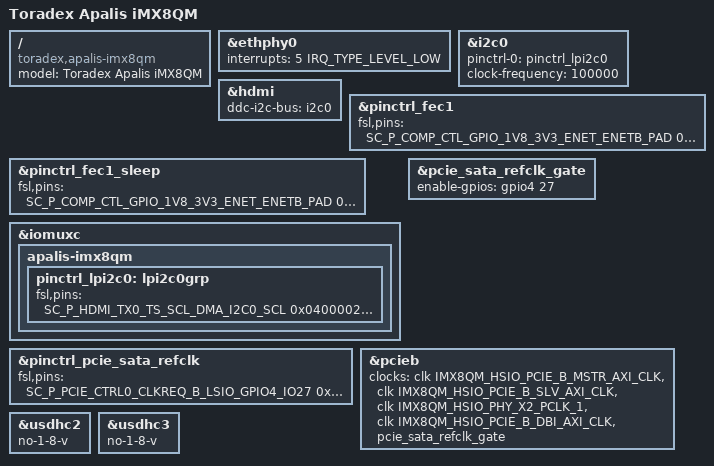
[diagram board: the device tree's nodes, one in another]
// SPDX-License-Identifier: GPL-2.0+ OR X11
/*
 * Copyright 2017-2020 Toradex
 */

#include "fsl-imx8qm-apalis-v1.1.dtsi"

/ {
	model = "Toradex Apalis iMX8QM";
	compatible = "toradex,apalis-imx8qm", "fsl,imx8qm";
};

/delete-node/ &pd_3v3_ext_rgmii;
/delete-node/ &pd_1v8_ext_rgmii;
/delete-node/ &pmbus_external_rgmii;
/delete-node/ &pcie_wifi_refclk;
/delete-node/ &pcie_wifi_refclk_gate;

&ethphy0 {
	interrupts = <5 IRQ_TYPE_LEVEL_LOW>;
};

/* Apalis I2C2 (DDC) */
&i2c0 {
	pinctrl-names = "default";
	pinctrl-0 = <&pinctrl_lpi2c0>;
	#address-cells = <1>;
	#size-cells = <0>;
	clock-frequency = <100000>;
};

&hdmi {
	ddc-i2c-bus = <&i2c0>;
};

&pinctrl_fec1 {
	fsl,pins = <
		SC_P_COMP_CTL_GPIO_1V8_3V3_ENET_ENETB_PAD	0x000014a0 /* Use pads in 1.8V mode */
		SC_P_ENET0_MDC_CONN_ENET0_MDC			0x06000020
		SC_P_ENET0_MDIO_CONN_ENET0_MDIO			0x06000020
		SC_P_ENET0_RGMII_TX_CTL_CONN_ENET0_RGMII_TX_CTL	0x06000020
		SC_P_ENET0_RGMII_TXC_CONN_ENET0_RGMII_TXC	0x06000020
		SC_P_ENET0_RGMII_TXD0_CONN_ENET0_RGMII_TXD0	0x06000020
		SC_P_ENET0_RGMII_TXD1_CONN_ENET0_RGMII_TXD1	0x06000020
		SC_P_ENET0_RGMII_TXD2_CONN_ENET0_RGMII_TXD2	0x06000020
		SC_P_ENET0_RGMII_TXD3_CONN_ENET0_RGMII_TXD3	0x06000020
		SC_P_ENET0_RGMII_RXC_CONN_ENET0_RGMII_RXC	0x06000020
		SC_P_ENET0_RGMII_RX_CTL_CONN_ENET0_RGMII_RX_CTL	0x06000020
		SC_P_ENET0_RGMII_RXD0_CONN_ENET0_RGMII_RXD0	0x06000020
		SC_P_ENET0_RGMII_RXD1_CONN_ENET0_RGMII_RXD1	0x06000020
		SC_P_ENET0_RGMII_RXD2_CONN_ENET0_RGMII_RXD2	0x06000020
		SC_P_ENET0_RGMII_RXD3_CONN_ENET0_RGMII_RXD3	0x06000020
		SC_P_ENET0_REFCLK_125M_25M_CONN_ENET0_REFCLK_125M_25M	0x06000020
		/* On-module ETH_RESET# */
		SC_P_LVDS1_GPIO01_LSIO_GPIO1_IO11		0x06000020
		/* On-module ETH_INT# */
		SC_P_LVDS0_GPIO01_LSIO_GPIO1_IO05		0x04000060
	>;
};

&pinctrl_fec1_sleep {
	fsl,pins = <
		SC_P_COMP_CTL_GPIO_1V8_3V3_ENET_ENETB_PAD	0x000014a0
		SC_P_ENET0_MDC_LSIO_GPIO4_IO14			0x04000040
		SC_P_ENET0_MDIO_LSIO_GPIO4_IO13			0x04000040
		SC_P_ENET0_RGMII_TX_CTL_LSIO_GPIO5_IO31		0x04000040
		SC_P_ENET0_RGMII_TXC_LSIO_GPIO5_IO30		0x04000040
		SC_P_ENET0_RGMII_TXD0_LSIO_GPIO6_IO00		0x04000040
		SC_P_ENET0_RGMII_TXD1_LSIO_GPIO6_IO01		0x04000040
		SC_P_ENET0_RGMII_TXD2_LSIO_GPIO6_IO02		0x04000040
		SC_P_ENET0_RGMII_TXD3_LSIO_GPIO6_IO03		0x04000040
		SC_P_ENET0_RGMII_RXC_LSIO_GPIO6_IO04		0x04000040
		SC_P_ENET0_RGMII_RX_CTL_LSIO_GPIO6_IO05		0x04000040
		SC_P_ENET0_RGMII_RXD0_LSIO_GPIO6_IO06		0x04000040
		SC_P_ENET0_RGMII_RXD1_LSIO_GPIO6_IO07		0x04000040
		SC_P_ENET0_RGMII_RXD2_LSIO_GPIO6_IO08		0x04000040
		SC_P_ENET0_RGMII_RXD3_LSIO_GPIO6_IO09		0x04000040
		SC_P_ENET0_REFCLK_125M_25M_LSIO_GPIO4_IO15	0x04000040
		SC_P_LVDS1_GPIO01_LSIO_GPIO1_IO11		0x04000040
		SC_P_LVDS0_GPIO01_LSIO_GPIO1_IO05		0x04000040
	>;
};

&iomuxc {
	apalis-imx8qm {
		/* Apalis I2C2 (DDC) */
		pinctrl_lpi2c0: lpi2c0grp {
			fsl,pins = <
				SC_P_HDMI_TX0_TS_SCL_DMA_I2C0_SCL	0x04000022
				SC_P_HDMI_TX0_TS_SDA_DMA_I2C0_SDA	0x04000022
			>;
		};
	};
};

/* On-module PCIe_CTRL0_CLKREQ */
&pinctrl_pcie_sata_refclk {
	fsl,pins = <
		SC_P_PCIE_CTRL0_CLKREQ_B_LSIO_GPIO4_IO27	0x00000021
	>;
};

&pcie_sata_refclk_gate {
	enable-gpios = <&gpio4 27 GPIO_ACTIVE_HIGH>;
};

/* On-module Wi-Fi */
&pcieb{
	clocks = <&clk IMX8QM_HSIO_PCIE_B_MSTR_AXI_CLK>,
		 <&clk IMX8QM_HSIO_PCIE_B_SLV_AXI_CLK>,
		 <&clk IMX8QM_HSIO_PHY_X2_PCLK_1>,
		 <&clk IMX8QM_HSIO_PCIE_B_DBI_AXI_CLK>,
		 <&pcie_sata_refclk_gate>;
};

/* Apalis MMC1 */
&usdhc2 {
	/*
	 * The PMIC on V1.0A HW generates 1.6V instead of 1.8V which creates
	 * issues with certain SD cards, disable 1.8V signaling for now.
	 */
	no-1-8-v;
};

/* Apalis SD1 */
&usdhc3 {
	/*
	 * The PMIC on V1.0A HW generates 1.6V instead of 1.8V which creates
	 * issues with certain SD cards, disable 1.8V signaling for now.
	 */
	no-1-8-v;
};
